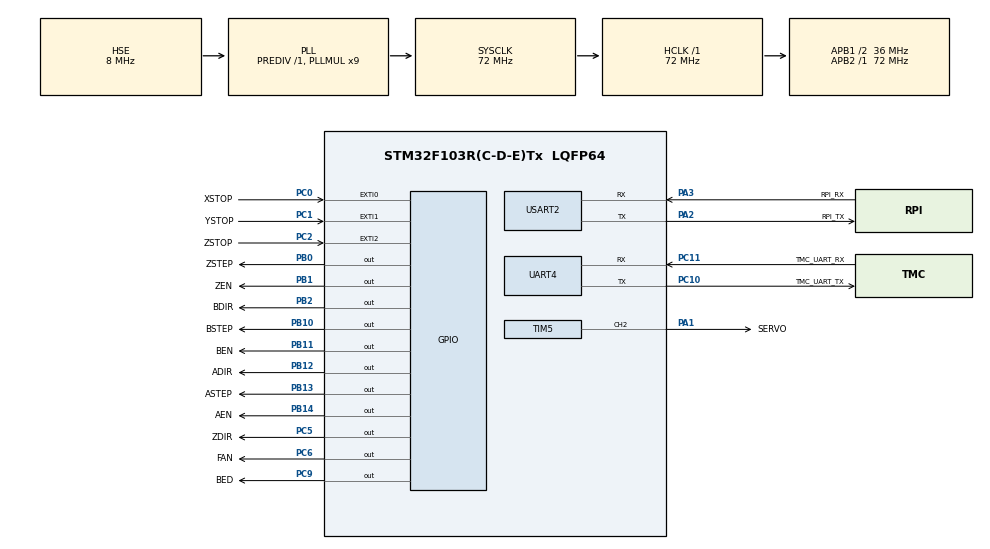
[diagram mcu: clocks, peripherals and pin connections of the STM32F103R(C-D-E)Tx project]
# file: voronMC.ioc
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Mcu.Family=STM32F1
Mcu.Name=STM32F103R(C-D-E)Tx
Mcu.Package=LQFP64
NVIC.EXTI0_IRQn=true\:0\:0\:false\:false\:true\:true\:true\:true
NVIC.EXTI1_IRQn=true\:0\:0\:false\:false\:true\:true\:true\:true
NVIC.EXTI2_IRQn=true\:0\:0\:false\:false\:true\:true\:true\:true
NVIC.PriorityGroup=NVIC_PRIORITYGROUP_4
NVIC.TIM1_UP_IRQn=true\:0\:0\:false\:false\:true\:true\:true\:true
NVIC.TIM2_IRQn=true\:0\:0\:false\:false\:true\:true\:true\:true
NVIC.TIM8_UP_IRQn=true\:0\:0\:false\:false\:true\:true\:true\:true
NVIC.USART2_IRQn=true\:0\:0\:false\:false\:true\:true\:true\:true
PA1.GPIO_Label=SERVO
PA1.Signal=S_TIM5_CH2
PA13.Mode=Serial_Wire
PA13.Signal=SYS_JTMS-SWDIO
PA14.Mode=Serial_Wire
PA14.Signal=SYS_JTCK-SWCLK
PA2.GPIO_Label=RPI_TX
PA2.Mode=Asynchronous
PA2.Signal=USART2_TX
PA3.GPIO_Label=RPI_RX
PA3.Mode=Asynchronous
PA3.Signal=USART2_RX
PB0.GPIO_Label=ZSTEP
PB0.Signal=GPIO_Output
PB1.GPIO_Label=ZEN
PB1.Signal=GPIO_Output
PB10.GPIO_Label=BSTEP
PB10.Signal=GPIO_Output
PB11.GPIO_Label=BEN
PB11.Signal=GPIO_Output
PB12.GPIO_Label=ADIR
PB12.Signal=GPIO_Output
PB13.GPIO_Label=ASTEP
PB13.Signal=GPIO_Output
PB14.GPIO_Label=AEN
PB14.Signal=GPIO_Output
PB2.GPIO_Label=BDIR
PB2.Signal=GPIO_Output
PC0.GPIO_Label=XSTOP
PC0.Signal=GPXTI0
PC1.GPIO_Label=YSTOP
PC1.Signal=GPXTI1
PC10.GPIO_Label=TMC_UART_TX
PC10.Mode=Asynchronous
PC10.Signal=UART4_TX
PC11.GPIO_Label=TMC_UART_RX
PC11.Mode=Asynchronous
PC11.Signal=UART4_RX
PC2.GPIO_Label=ZSTOP
PC2.Signal=GPXTI2
PC5.GPIO_Label=ZDIR
PC5.Signal=GPIO_Output
PC6.GPIO_Label=FAN
PC6.Signal=GPIO_Output
PC9.GPIO_Label=BED
PC9.Signal=GPIO_Output
PD0-OSC_IN.Mode=HSE-External-Oscillator
PD0-OSC_IN.Signal=RCC_OSC_IN
PD1-OSC_OUT.Mode=HSE-External-Oscillator
PD1-OSC_OUT.Signal=RCC_OSC_OUT
ProjectManager.HeapSize=0x200
ProjectManager.StackSize=0x400
ProjectManager.TargetToolchain=STM32CubeIDE
RCC.AHBFreq_Value=72000000
RCC.APB1CLKDivider=RCC_HCLK_DIV2
RCC.APB1Freq_Value=36000000
RCC.APB1TimFreq_Value=72000000
RCC.APB2Freq_Value=72000000
RCC.APB2TimFreq_Value=72000000
RCC.HCLKFreq_Value=72000000
RCC.PLLMUL=RCC_PLL_MUL9
RCC.PLLSourceVirtual=RCC_PLLSOURCE_HSE
RCC.SYSCLKFreq_VALUE=72000000
RCC.SYSCLKSource=RCC_SYSCLKSOURCE_PLLCLK
RCC.USBFreq_Value=48000000
RCC.USBPrescaler=RCC_USBCLKSOURCE_PLL_DIV1_5
SH.S_TIM5_CH2.0=TIM5_CH2,PWM Generation2 CH2
TIM1.AutoReloadPreload=TIM_AUTORELOAD_PRELOAD_ENABLE
TIM1.Prescaler=71
TIM2.AutoReloadPreload=TIM_AUTORELOAD_PRELOAD_ENABLE
TIM2.Prescaler=71
TIM5.AutoReloadPreload=TIM_AUTORELOAD_PRELOAD_ENABLE
TIM5.Channel-PWM\ Generation2\ CH2=TIM_CHANNEL_2
TIM5.Period=19999
TIM5.Prescaler=71
TIM8.AutoReloadPreload=TIM_AUTORELOAD_PRELOAD_ENABLE
TIM8.Prescaler=71
UART4.VirtualMode=Asynchronous
USART2.VirtualMode=VM_ASYNC
VP_TIM1_VS_ClockSourceINT.Mode=Internal
VP_TIM2_VS_ClockSourceINT.Mode=Internal
VP_TIM5_VS_ClockSourceINT.Mode=Internal
VP_TIM8_VS_ClockSourceINT.Mode=Internal
board=custom

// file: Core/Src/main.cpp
/* USER CODE BEGIN Header */
/**
  ******************************************************************************
  * @file           : main.c
  * @brief          : Main program body
  ******************************************************************************
  * @attention
  *
  * Copyright (c) 2026 STMicroelectronics.
  * All rights reserved.
  *
  * This software is licensed under terms that can be found in the LICENSE file
  * in the root directory of this software component.
  * If no LICENSE file comes with this software, it is provided AS-IS.
  *
  ******************************************************************************
  */
/* USER CODE END Header */
#include "main.h"

/* USER CODE BEGIN Includes */
#include "app.h"
#include "Config.h"
/* USER CODE END Includes */

TIM_HandleTypeDef htim1;
TIM_HandleTypeDef htim2;
TIM_HandleTypeDef htim5;
TIM_HandleTypeDef htim8;

UART_HandleTypeDef huart4;
UART_HandleTypeDef huart2;

void SystemClock_Config(void);
static void MX_GPIO_Init(void);
static void MX_TIM1_Init(void);
static void MX_TIM2_Init(void);
static void MX_TIM5_Init(void);
static void MX_TIM8_Init(void);
static void MX_UART4_Init(void);
static void MX_USART2_UART_Init(void);

int main(void)
{

  /* MCU Configuration--------------------------------------------------------*/

  /* Reset of all peripherals, Initializes the Flash interface and the Systick. */
  HAL_Init();

  /* Configure the system clock */
  SystemClock_Config();

  /* Initialize all configured peripherals */
  MX_GPIO_Init();
  MX_TIM1_Init();
  MX_TIM2_Init();
  MX_TIM5_Init();
  MX_TIM8_Init();
  MX_UART4_Init();
  MX_USART2_UART_Init();
  app_init();
  /* Infinite loop */
  /* USER CODE BEGIN WHILE */
  while (1)
  {
	app_while();
    /* USER CODE END WHILE */

  }
}

void SystemClock_Config(void)
{
  RCC_OscInitTypeDef RCC_OscInitStruct = {0};
  RCC_ClkInitTypeDef RCC_ClkInitStruct = {0};

  /** Initializes the RCC Oscillators according to the specified parameters
  * in the RCC_OscInitTypeDef structure.
  */
  RCC_OscInitStruct.OscillatorType = RCC_OSCILLATORTYPE_HSE;
  RCC_OscInitStruct.HSEState = RCC_HSE_ON;
  RCC_OscInitStruct.HSEPredivValue = RCC_HSE_PREDIV_DIV1;
  RCC_OscInitStruct.HSIState = RCC_HSI_ON;
  RCC_OscInitStruct.PLL.PLLState = RCC_PLL_ON;
  RCC_OscInitStruct.PLL.PLLSource = RCC_PLLSOURCE_HSE;
  RCC_OscInitStruct.PLL.PLLMUL = RCC_PLL_MUL9;
  if (HAL_RCC_OscConfig(&RCC_OscInitStruct) != HAL_OK)
  {
    Error_Handler();
  }

  /** Initializes the CPU, AHB and APB buses clocks
  */
  RCC_ClkInitStruct.ClockType = RCC_CLOCKTYPE_HCLK|RCC_CLOCKTYPE_SYSCLK
                              |RCC_CLOCKTYPE_PCLK1|RCC_CLOCKTYPE_PCLK2;
  RCC_ClkInitStruct.SYSCLKSource = RCC_SYSCLKSOURCE_PLLCLK;
  RCC_ClkInitStruct.AHBCLKDivider = RCC_SYSCLK_DIV1;
  RCC_ClkInitStruct.APB1CLKDivider = RCC_HCLK_DIV2;
  RCC_ClkInitStruct.APB2CLKDivider = RCC_HCLK_DIV1;

  if (HAL_RCC_ClockConfig(&RCC_ClkInitStruct, FLASH_LATENCY_2) != HAL_OK)
  {
    Error_Handler();
  }
}

static void MX_TIM1_Init(void)
{

  TIM_ClockConfigTypeDef sClockSourceConfig = {0};
  TIM_MasterConfigTypeDef sMasterConfig = {0};

  htim1.Instance = TIM1;
  htim1.Init.Prescaler = 71;
  htim1.Init.CounterMode = TIM_COUNTERMODE_UP;
  htim1.Init.Period = 65535;
  htim1.Init.ClockDivision = TIM_CLOCKDIVISION_DIV1;
  htim1.Init.RepetitionCounter = 0;
  htim1.Init.AutoReloadPreload = TIM_AUTORELOAD_PRELOAD_ENABLE;
  if (HAL_TIM_Base_Init(&htim1) != HAL_OK)
  {
    Error_Handler();
  }
  sClockSourceConfig.ClockSource = TIM_CLOCKSOURCE_INTERNAL;
  if (HAL_TIM_ConfigClockSource(&htim1, &sClockSourceConfig) != HAL_OK)
  {
    Error_Handler();
  }
  sMasterConfig.MasterOutputTrigger = TIM_TRGO_RESET;
  sMasterConfig.MasterSlaveMode = TIM_MASTERSLAVEMODE_DISABLE;
  if (HAL_TIMEx_MasterConfigSynchronization(&htim1, &sMasterConfig) != HAL_OK)
  {
    Error_Handler();
  }

}

static void MX_TIM2_Init(void)
{

  TIM_ClockConfigTypeDef sClockSourceConfig = {0};
  TIM_MasterConfigTypeDef sMasterConfig = {0};

  htim2.Instance = TIM2;
  htim2.Init.Prescaler = 71;
  htim2.Init.CounterMode = TIM_COUNTERMODE_UP;
  htim2.Init.Period = 65535;
  htim2.Init.ClockDivision = TIM_CLOCKDIVISION_DIV1;
  htim2.Init.AutoReloadPreload = TIM_AUTORELOAD_PRELOAD_ENABLE;
  if (HAL_TIM_Base_Init(&htim2) != HAL_OK)
  {
    Error_Handler();
  }
  sClockSourceConfig.ClockSource = TIM_CLOCKSOURCE_INTERNAL;
  if (HAL_TIM_ConfigClockSource(&htim2, &sClockSourceConfig) != HAL_OK)
  {
    Error_Handler();
  }
  sMasterConfig.MasterOutputTrigger = TIM_TRGO_RESET;
  sMasterConfig.MasterSlaveMode = TIM_MASTERSLAVEMODE_DISABLE;
  if (HAL_TIMEx_MasterConfigSynchronization(&htim2, &sMasterConfig) != HAL_OK)
  {
    Error_Handler();
  }

}

static void MX_TIM5_Init(void)
{

  TIM_ClockConfigTypeDef sClockSourceConfig = {0};
  TIM_MasterConfigTypeDef sMasterConfig = {0};
  TIM_OC_InitTypeDef sConfigOC = {0};

  htim5.Instance = TIM5;
  htim5.Init.Prescaler = 71;
  htim5.Init.CounterMode = TIM_COUNTERMODE_UP;
  htim5.Init.Period = 19999;
  htim5.Init.ClockDivision = TIM_CLOCKDIVISION_DIV1;
  htim5.Init.AutoReloadPreload = TIM_AUTORELOAD_PRELOAD_ENABLE;
  if (HAL_TIM_Base_Init(&htim5) != HAL_OK)
  {
    Error_Handler();
  }
  sClockSourceConfig.ClockSource = TIM_CLOCKSOURCE_INTERNAL;
  if (HAL_TIM_ConfigClockSource(&htim5, &sClockSourceConfig) != HAL_OK)
  {
    Error_Handler();
  }
  if (HAL_TIM_PWM_Init(&htim5) != HAL_OK)
  {
    Error_Handler();
  }
  sMasterConfig.MasterOutputTrigger = TIM_TRGO_RESET;
  sMasterConfig.MasterSlaveMode = TIM_MASTERSLAVEMODE_DISABLE;
  if (HAL_TIMEx_MasterConfigSynchronization(&htim5, &sMasterConfig) != HAL_OK)
  {
    Error_Handler();
  }
  sConfigOC.OCMode = TIM_OCMODE_PWM1;
  sConfigOC.Pulse = 0;
  sConfigOC.OCPolarity = TIM_OCPOLARITY_HIGH;
  sConfigOC.OCFastMode = TIM_OCFAST_DISABLE;
  if (HAL_TIM_PWM_ConfigChannel(&htim5, &sConfigOC, TIM_CHANNEL_2) != HAL_OK)
  {
    Error_Handler();
  }
  HAL_TIM_MspPostInit(&htim5);

}

static void MX_TIM8_Init(void)
{

  TIM_ClockConfigTypeDef sClockSourceConfig = {0};
  TIM_MasterConfigTypeDef sMasterConfig = {0};

  htim8.Instance = TIM8;
  htim8.Init.Prescaler = 71;
  htim8.Init.CounterMode = TIM_COUNTERMODE_UP;
  htim8.Init.Period = 65535;
  htim8.Init.ClockDivision = TIM_CLOCKDIVISION_DIV1;
  htim8.Init.RepetitionCounter = 0;
  htim8.Init.AutoReloadPreload = TIM_AUTORELOAD_PRELOAD_ENABLE;
  if (HAL_TIM_Base_Init(&htim8) != HAL_OK)
  {
    Error_Handler();
  }
  sClockSourceConfig.ClockSource = TIM_CLOCKSOURCE_INTERNAL;
  if (HAL_TIM_ConfigClockSource(&htim8, &sClockSourceConfig) != HAL_OK)
  {
    Error_Handler();
  }
  sMasterConfig.MasterOutputTrigger = TIM_TRGO_RESET;
  sMasterConfig.MasterSlaveMode = TIM_MASTERSLAVEMODE_DISABLE;
  if (HAL_TIMEx_MasterConfigSynchronization(&htim8, &sMasterConfig) != HAL_OK)
  {
    Error_Handler();
  }

}

static void MX_UART4_Init(void)
{

  huart4.Instance = UART4;
  huart4.Init.BaudRate = 115200;
  huart4.Init.WordLength = UART_WORDLENGTH_8B;
  huart4.Init.StopBits = UART_STOPBITS_1;
  huart4.Init.Parity = UART_PARITY_NONE;
  huart4.Init.Mode = UART_MODE_TX_RX;
  huart4.Init.HwFlowCtl = UART_HWCONTROL_NONE;
  huart4.Init.OverSampling = UART_OVERSAMPLING_16;
  if (HAL_UART_Init(&huart4) != HAL_OK)
  {
    Error_Handler();
  }

}

static void MX_USART2_UART_Init(void)
{

  huart2.Instance = USART2;
  huart2.Init.BaudRate = 115200;
  huart2.Init.WordLength = UART_WORDLENGTH_8B;
  huart2.Init.StopBits = UART_STOPBITS_1;
  huart2.Init.Parity = UART_PARITY_NONE;
  huart2.Init.Mode = UART_MODE_TX_RX;
  huart2.Init.HwFlowCtl = UART_HWCONTROL_NONE;
  huart2.Init.OverSampling = UART_OVERSAMPLING_16;
  if (HAL_UART_Init(&huart2) != HAL_OK)
  {
    Error_Handler();
  }

}

static void MX_GPIO_Init(void)
{
  GPIO_InitTypeDef GPIO_InitStruct = {0};

  /* GPIO Ports Clock Enable */
  __HAL_RCC_GPIOD_CLK_ENABLE();
  __HAL_RCC_GPIOC_CLK_ENABLE();
  __HAL_RCC_GPIOA_CLK_ENABLE();
  __HAL_RCC_GPIOB_CLK_ENABLE();

  /*Configure GPIO pin Output Level */
  HAL_GPIO_WritePin(GPIOC, ZDIR_Pin|FAN_Pin|BED_Pin, GPIO_PIN_RESET);

  /*Configure GPIO pin Output Level */
  HAL_GPIO_WritePin(GPIOB, ZSTEP_Pin|ZEN_Pin|BDIR_Pin|BSTEP_Pin
                          |BEN_Pin|ADIR_Pin|ASTEP_Pin|AEN_Pin, GPIO_PIN_RESET);

  /*Configure GPIO pins : XSTOP_Pin YSTOP_Pin ZSTOP_Pin */
  GPIO_InitStruct.Pin = XSTOP_Pin|YSTOP_Pin|ZSTOP_Pin;
  GPIO_InitStruct.Mode = GPIO_MODE_IT_RISING;
  GPIO_InitStruct.Pull = GPIO_NOPULL;
  HAL_GPIO_Init(GPIOC, &GPIO_InitStruct);

  /*Configure GPIO pins : ZDIR_Pin FAN_Pin BED_Pin */
  GPIO_InitStruct.Pin = ZDIR_Pin|FAN_Pin|BED_Pin;
  GPIO_InitStruct.Mode = GPIO_MODE_OUTPUT_PP;
  GPIO_InitStruct.Pull = GPIO_NOPULL;
  GPIO_InitStruct.Speed = GPIO_SPEED_FREQ_LOW;
  HAL_GPIO_Init(GPIOC, &GPIO_InitStruct);

  /*Configure GPIO pins : ZSTEP_Pin ZEN_Pin BDIR_Pin BSTEP_Pin
                           BEN_Pin ADIR_Pin ASTEP_Pin AEN_Pin */
  GPIO_InitStruct.Pin = ZSTEP_Pin|ZEN_Pin|BDIR_Pin|BSTEP_Pin
                          |BEN_Pin|ADIR_Pin|ASTEP_Pin|AEN_Pin;
  GPIO_InitStruct.Mode = GPIO_MODE_OUTPUT_PP;
  GPIO_InitStruct.Pull = GPIO_NOPULL;
  GPIO_InitStruct.Speed = GPIO_SPEED_FREQ_LOW;
  HAL_GPIO_Init(GPIOB, &GPIO_InitStruct);

  /* EXTI interrupt init*/
  HAL_NVIC_SetPriority(EXTI0_IRQn, 0, 0);
  HAL_NVIC_EnableIRQ(EXTI0_IRQn);

  HAL_NVIC_SetPriority(EXTI1_IRQn, 0, 0);
  HAL_NVIC_EnableIRQ(EXTI1_IRQn);

  HAL_NVIC_SetPriority(EXTI2_IRQn, 0, 0);
  HAL_NVIC_EnableIRQ(EXTI2_IRQn);

}

void Error_Handler(void)
{
  __disable_irq();
  while (1)
  {
  }
}
